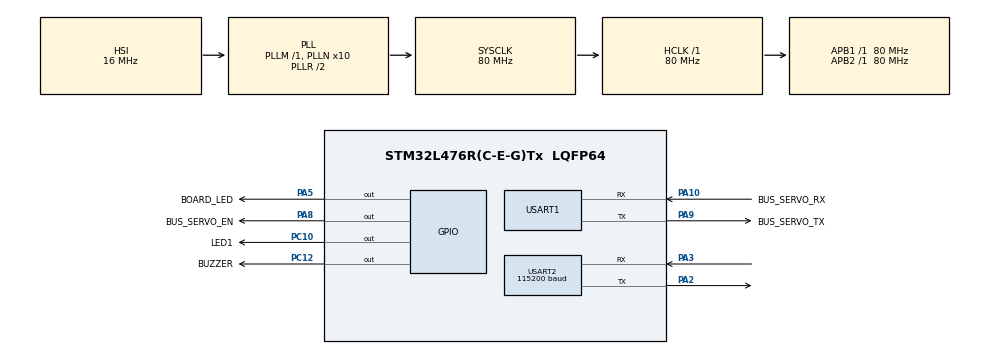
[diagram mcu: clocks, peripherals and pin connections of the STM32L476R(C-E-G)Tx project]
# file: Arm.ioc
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Dma.Request0=USART2_RX
Dma.Request1=USART2_TX
Dma.USART2_RX.0.Direction=DMA_PERIPH_TO_MEMORY
Dma.USART2_RX.0.Instance=DMA1_Channel6
Dma.USART2_RX.0.MemDataAlignment=DMA_MDATAALIGN_BYTE
Dma.USART2_RX.0.MemInc=DMA_MINC_ENABLE
Dma.USART2_RX.0.Mode=DMA_NORMAL
Dma.USART2_RX.0.PeriphDataAlignment=DMA_PDATAALIGN_BYTE
Dma.USART2_RX.0.PeriphInc=DMA_PINC_DISABLE
Dma.USART2_RX.0.Priority=DMA_PRIORITY_LOW
Dma.USART2_TX.1.Direction=DMA_MEMORY_TO_PERIPH
Dma.USART2_TX.1.Instance=DMA1_Channel7
Dma.USART2_TX.1.MemDataAlignment=DMA_MDATAALIGN_BYTE
Dma.USART2_TX.1.MemInc=DMA_MINC_ENABLE
Dma.USART2_TX.1.Mode=DMA_NORMAL
Dma.USART2_TX.1.PeriphDataAlignment=DMA_PDATAALIGN_BYTE
Dma.USART2_TX.1.PeriphInc=DMA_PINC_DISABLE
Dma.USART2_TX.1.Priority=DMA_PRIORITY_LOW
Mcu.Family=STM32L4
Mcu.Name=STM32L476R(C-E-G)Tx
Mcu.Package=LQFP64
NVIC.DMA1_Channel6_IRQn=true\:0\:0\:false\:false\:true\:false\:true\:true
NVIC.DMA1_Channel7_IRQn=true\:0\:0\:false\:false\:true\:false\:true\:true
NVIC.PriorityGroup=NVIC_PRIORITYGROUP_4
NVIC.USART1_IRQn=true\:0\:0\:false\:false\:true\:true\:true\:true
NVIC.USART2_IRQn=true\:0\:0\:false\:false\:true\:true\:true\:true
PA10.GPIO_Label=BUS_SERVO_RX
PA10.GPIO_PuPd=GPIO_NOPULL
PA10.GPIO_Speed=GPIO_SPEED_FREQ_VERY_HIGH
PA10.Mode=Asynchronous
PA10.Signal=USART1_RX
PA2.Mode=Asynchronous
PA2.Signal=USART2_TX
PA3.Mode=Asynchronous
PA3.Signal=USART2_RX
PA5.GPIO_Label=BOARD_LED
PA5.Signal=GPIO_Output
PA8.GPIO_Label=BUS_SERVO_EN
PA8.GPIO_Speed=GPIO_SPEED_FREQ_HIGH
PA8.PinState=GPIO_PIN_RESET
PA8.Signal=GPIO_Output
PA9.GPIO_Label=BUS_SERVO_TX
PA9.Mode=Asynchronous
PA9.Signal=USART1_TX
PC10.GPIO_Label=LED1
PC10.Signal=GPIO_Output
PC12.GPIO_Label=BUZZER
PC12.Signal=GPIO_Output
PH0-OSC_IN\ (PH0).Mode=HSE-External-Oscillator
PH0-OSC_IN\ (PH0).Signal=RCC_OSC_IN
PH1-OSC_OUT\ (PH1).Mode=HSE-External-Oscillator
PH1-OSC_OUT\ (PH1).Signal=RCC_OSC_OUT
ProjectManager.HeapSize=0x200
ProjectManager.StackSize=0x400
ProjectManager.TargetToolchain=CMake
RCC.ADCFreq_Value=64000000
RCC.AHBFreq_Value=80000000
RCC.APB1Freq_Value=80000000
RCC.APB1TimFreq_Value=80000000
RCC.APB2Freq_Value=80000000
RCC.APB2TimFreq_Value=80000000
RCC.CortexFreq_Value=80000000
RCC.HCLKFreq_Value=80000000
RCC.HSE_VALUE=16000000
RCC.HSI_VALUE=16000000
RCC.LSE_VALUE=32768
RCC.MSI_VALUE=4000000
RCC.PLLN=10
RCC.PLLSourceVirtual=RCC_PLLSOURCE_HSI
RCC.SYSCLKFreq_VALUE=80000000
RCC.SYSCLKSource=RCC_SYSCLKSOURCE_PLLCLK
RCC.USBFreq_Value=64000000
RCC.VCOOutputFreq_Value=160000000
USART1.VirtualMode-Asynchronous=VM_ASYNC
USART2.BaudRate=115200
USART2.VirtualMode-Asynchronous=VM_ASYNC
board=custom

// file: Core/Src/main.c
/* USER CODE BEGIN Header */
/**
  ******************************************************************************
  * @file           : main.c
  * @brief          : Main program body
  ******************************************************************************
  * @attention
  *
  * Copyright (c) 2026 STMicroelectronics.
  * All rights reserved.
  *
  * This software is licensed under terms that can be found in the LICENSE file
  * in the root directory of this software component.
  * If no LICENSE file comes with this software, it is provided AS-IS.
  *
  ******************************************************************************
  */
/* USER CODE END Header */
#include "main.h"
#include "dma.h"
#include "usart.h"
#include "gpio.h"

/* USER CODE BEGIN Includes */

//////////* Headers *//////////
/* STD */

/* Arm */
//// User
// Core
#include "core.h"
// Peripheral
#include "buzzer.h"
#include "bus_servo.h"
#include "led.h"
///////////////////////////////

/* USER CODE END Includes */

void SystemClock_Config(void);

int main(void)
{

  /* MCU Configuration--------------------------------------------------------*/

  /* Reset of all peripherals, Initializes the Flash interface and the Systick. */
  HAL_Init();

  /* Configure the system clock */
  SystemClock_Config();

  /* Initialize all configured peripherals */
  MX_GPIO_Init();
  MX_DMA_Init();
  MX_USART1_UART_Init();
  MX_USART2_UART_Init();
  /* USER CODE BEGIN 2 */
  // Initialize peripherals
  initialize_bus_servo();
  initialize_buzzer();
  initialize_led();

  // Initialize core
  initialize_core();

  /* USER CODE END 2 */

  /* Infinite loop */
  /* USER CODE BEGIN WHILE */
  while (true) {
    /* USER CODE END WHILE */

    /* USER CODE BEGIN 3 */
    receive_packet_from_core();

    execute_bus_servo_task();
    execute_buzzer_task();
    execute_led_task();
  }
  /* USER CODE END 3 */
}

void SystemClock_Config(void)
{
  RCC_OscInitTypeDef RCC_OscInitStruct = {0};
  RCC_ClkInitTypeDef RCC_ClkInitStruct = {0};

  /** Configure the main internal regulator output voltage
  */
  if (HAL_PWREx_ControlVoltageScaling(PWR_REGULATOR_VOLTAGE_SCALE1) != HAL_OK)
  {
    Error_Handler();
  }

  /** Initializes the RCC Oscillators according to the specified parameters
  * in the RCC_OscInitTypeDef structure.
  */
  RCC_OscInitStruct.OscillatorType = RCC_OSCILLATORTYPE_HSI;
  RCC_OscInitStruct.HSIState = RCC_HSI_ON;
  RCC_OscInitStruct.HSICalibrationValue = RCC_HSICALIBRATION_DEFAULT;
  RCC_OscInitStruct.PLL.PLLState = RCC_PLL_ON;
  RCC_OscInitStruct.PLL.PLLSource = RCC_PLLSOURCE_HSI;
  RCC_OscInitStruct.PLL.PLLM = 1;
  RCC_OscInitStruct.PLL.PLLN = 10;
  RCC_OscInitStruct.PLL.PLLP = RCC_PLLP_DIV7;
  RCC_OscInitStruct.PLL.PLLQ = RCC_PLLQ_DIV2;
  RCC_OscInitStruct.PLL.PLLR = RCC_PLLR_DIV2;
  if (HAL_RCC_OscConfig(&RCC_OscInitStruct) != HAL_OK)
  {
    Error_Handler();
  }

  /** Initializes the CPU, AHB and APB buses clocks
  */
  RCC_ClkInitStruct.ClockType = RCC_CLOCKTYPE_HCLK|RCC_CLOCKTYPE_SYSCLK
                              |RCC_CLOCKTYPE_PCLK1|RCC_CLOCKTYPE_PCLK2;
  RCC_ClkInitStruct.SYSCLKSource = RCC_SYSCLKSOURCE_PLLCLK;
  RCC_ClkInitStruct.AHBCLKDivider = RCC_SYSCLK_DIV1;
  RCC_ClkInitStruct.APB1CLKDivider = RCC_HCLK_DIV1;
  RCC_ClkInitStruct.APB2CLKDivider = RCC_HCLK_DIV1;

  if (HAL_RCC_ClockConfig(&RCC_ClkInitStruct, FLASH_LATENCY_4) != HAL_OK)
  {
    Error_Handler();
  }
}

void Error_Handler(void)
{
  __disable_irq();
  while (1)
  {
  }
}
